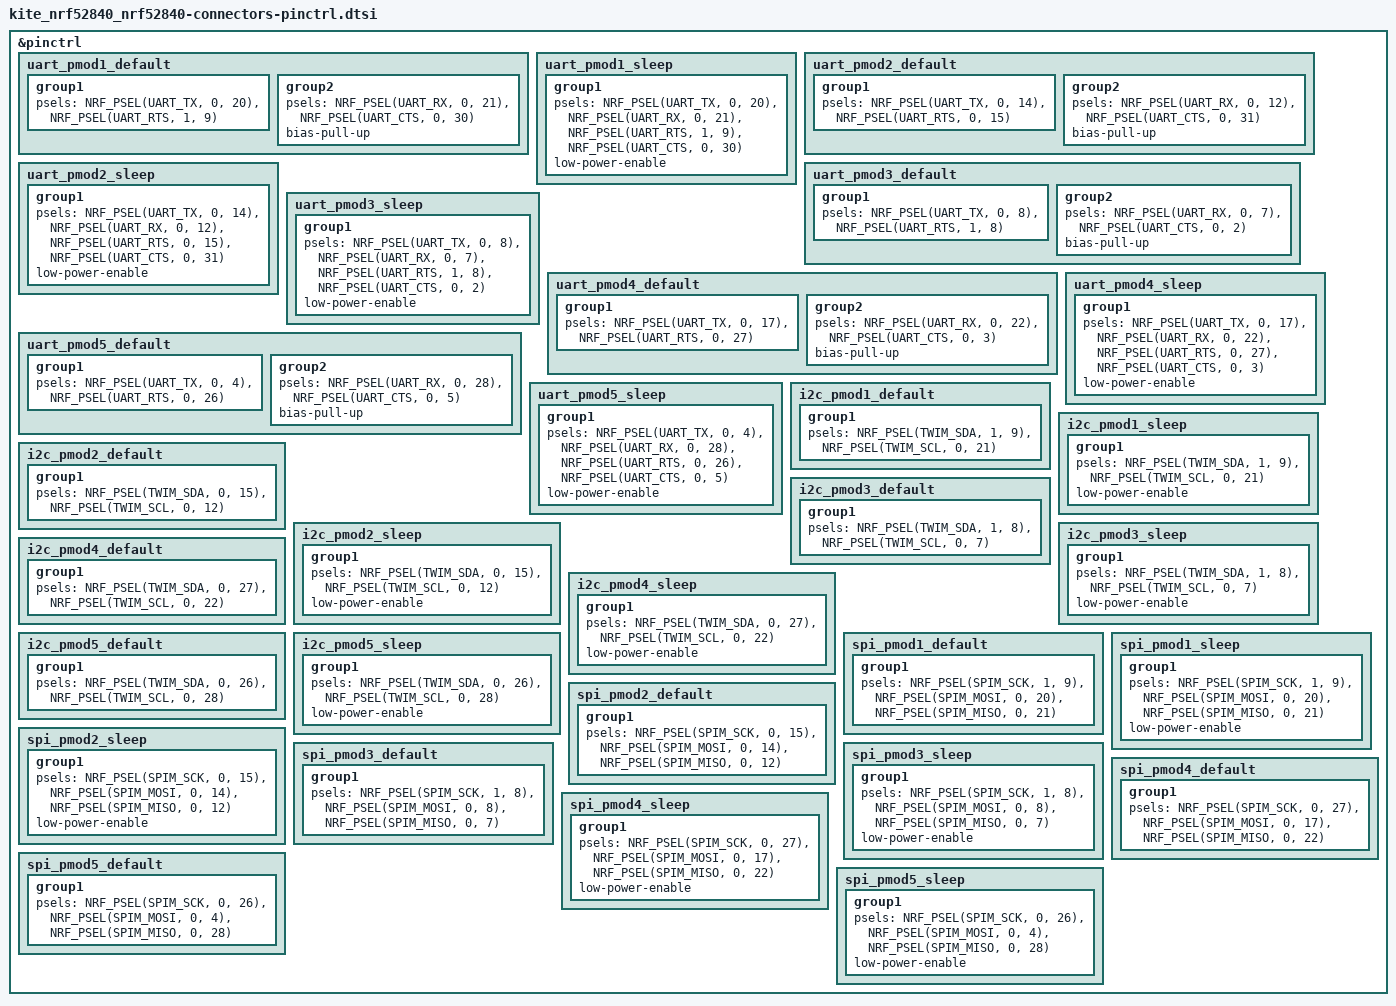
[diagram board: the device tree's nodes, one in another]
/*
 * NOTE: Autogenerated file using gen-connectors-dtsi.py
 *
 * SPDX-License-Identifier: Apache-2.0
 */

&pinctrl {
	/* UART */

	/omit-if-no-ref/ uart_pmod1_default: uart_pmod1_default {
		group1 {
			psels = <NRF_PSEL(UART_TX, 0, 20)>,
				<NRF_PSEL(UART_RTS, 1, 9)>;
		};
		group2 {
			psels = <NRF_PSEL(UART_RX, 0, 21)>,
				<NRF_PSEL(UART_CTS, 0, 30)>;
			bias-pull-up;
		};
	};

	/omit-if-no-ref/ uart_pmod1_sleep: uart_pmod1_sleep {
		group1 {
			psels = <NRF_PSEL(UART_TX, 0, 20)>,
				<NRF_PSEL(UART_RX, 0, 21)>,
				<NRF_PSEL(UART_RTS, 1, 9)>,
				<NRF_PSEL(UART_CTS, 0, 30)>;
			low-power-enable;
		};
	};

	/omit-if-no-ref/ uart_pmod2_default: uart_pmod2_default {
		group1 {
			psels = <NRF_PSEL(UART_TX, 0, 14)>,
				<NRF_PSEL(UART_RTS, 0, 15)>;
		};
		group2 {
			psels = <NRF_PSEL(UART_RX, 0, 12)>,
				<NRF_PSEL(UART_CTS, 0, 31)>;
			bias-pull-up;
		};
	};

	/omit-if-no-ref/ uart_pmod2_sleep: uart_pmod2_sleep {
		group1 {
			psels = <NRF_PSEL(UART_TX, 0, 14)>,
				<NRF_PSEL(UART_RX, 0, 12)>,
				<NRF_PSEL(UART_RTS, 0, 15)>,
				<NRF_PSEL(UART_CTS, 0, 31)>;
			low-power-enable;
		};
	};

	/omit-if-no-ref/ uart_pmod3_default: uart_pmod3_default {
		group1 {
			psels = <NRF_PSEL(UART_TX, 0, 8)>,
				<NRF_PSEL(UART_RTS, 1, 8)>;
		};
		group2 {
			psels = <NRF_PSEL(UART_RX, 0, 7)>,
				<NRF_PSEL(UART_CTS, 0, 2)>;
			bias-pull-up;
		};
	};

	/omit-if-no-ref/ uart_pmod3_sleep: uart_pmod3_sleep {
		group1 {
			psels = <NRF_PSEL(UART_TX, 0, 8)>,
				<NRF_PSEL(UART_RX, 0, 7)>,
				<NRF_PSEL(UART_RTS, 1, 8)>,
				<NRF_PSEL(UART_CTS, 0, 2)>;
			low-power-enable;
		};
	};

	/omit-if-no-ref/ uart_pmod4_default: uart_pmod4_default {
		group1 {
			psels = <NRF_PSEL(UART_TX, 0, 17)>,
				<NRF_PSEL(UART_RTS, 0, 27)>;
		};
		group2 {
			psels = <NRF_PSEL(UART_RX, 0, 22)>,
				<NRF_PSEL(UART_CTS, 0, 3)>;
			bias-pull-up;
		};
	};

	/omit-if-no-ref/ uart_pmod4_sleep: uart_pmod4_sleep {
		group1 {
			psels = <NRF_PSEL(UART_TX, 0, 17)>,
				<NRF_PSEL(UART_RX, 0, 22)>,
				<NRF_PSEL(UART_RTS, 0, 27)>,
				<NRF_PSEL(UART_CTS, 0, 3)>;
			low-power-enable;
		};
	};

	/omit-if-no-ref/ uart_pmod5_default: uart_pmod5_default {
		group1 {
			psels = <NRF_PSEL(UART_TX, 0, 4)>,
				<NRF_PSEL(UART_RTS, 0, 26)>;
		};
		group2 {
			psels = <NRF_PSEL(UART_RX, 0, 28)>,
				<NRF_PSEL(UART_CTS, 0, 5)>;
			bias-pull-up;
		};
	};

	/omit-if-no-ref/ uart_pmod5_sleep: uart_pmod5_sleep {
		group1 {
			psels = <NRF_PSEL(UART_TX, 0, 4)>,
				<NRF_PSEL(UART_RX, 0, 28)>,
				<NRF_PSEL(UART_RTS, 0, 26)>,
				<NRF_PSEL(UART_CTS, 0, 5)>;
			low-power-enable;
		};
	};


	/* I2C */

	/omit-if-no-ref/ i2c_pmod1_default: i2c_pmod1_default {
		group1 {
			psels = <NRF_PSEL(TWIM_SDA, 1, 9)>,
				<NRF_PSEL(TWIM_SCL, 0, 21)>;
		};
	};

	/omit-if-no-ref/ i2c_pmod1_sleep: i2c_pmod1_sleep {
		group1 {
			psels = <NRF_PSEL(TWIM_SDA, 1, 9)>,
				<NRF_PSEL(TWIM_SCL, 0, 21)>;
			low-power-enable;
		};
	};

	/omit-if-no-ref/ i2c_pmod2_default: i2c_pmod2_default {
		group1 {
			psels = <NRF_PSEL(TWIM_SDA, 0, 15)>,
				<NRF_PSEL(TWIM_SCL, 0, 12)>;
		};
	};

	/omit-if-no-ref/ i2c_pmod2_sleep: i2c_pmod2_sleep {
		group1 {
			psels = <NRF_PSEL(TWIM_SDA, 0, 15)>,
				<NRF_PSEL(TWIM_SCL, 0, 12)>;
			low-power-enable;
		};
	};

	/omit-if-no-ref/ i2c_pmod3_default: i2c_pmod3_default {
		group1 {
			psels = <NRF_PSEL(TWIM_SDA, 1, 8)>,
				<NRF_PSEL(TWIM_SCL, 0, 7)>;
		};
	};

	/omit-if-no-ref/ i2c_pmod3_sleep: i2c_pmod3_sleep {
		group1 {
			psels = <NRF_PSEL(TWIM_SDA, 1, 8)>,
				<NRF_PSEL(TWIM_SCL, 0, 7)>;
			low-power-enable;
		};
	};

	/omit-if-no-ref/ i2c_pmod4_default: i2c_pmod4_default {
		group1 {
			psels = <NRF_PSEL(TWIM_SDA, 0, 27)>,
				<NRF_PSEL(TWIM_SCL, 0, 22)>;
		};
	};

	/omit-if-no-ref/ i2c_pmod4_sleep: i2c_pmod4_sleep {
		group1 {
			psels = <NRF_PSEL(TWIM_SDA, 0, 27)>,
				<NRF_PSEL(TWIM_SCL, 0, 22)>;
			low-power-enable;
		};
	};

	/omit-if-no-ref/ i2c_pmod5_default: i2c_pmod5_default {
		group1 {
			psels = <NRF_PSEL(TWIM_SDA, 0, 26)>,
				<NRF_PSEL(TWIM_SCL, 0, 28)>;
		};
	};

	/omit-if-no-ref/ i2c_pmod5_sleep: i2c_pmod5_sleep {
		group1 {
			psels = <NRF_PSEL(TWIM_SDA, 0, 26)>,
				<NRF_PSEL(TWIM_SCL, 0, 28)>;
			low-power-enable;
		};
	};


	/* SPI */

	/omit-if-no-ref/ spi_pmod1_default: spi_pmod1_default {
		group1 {
			psels = <NRF_PSEL(SPIM_SCK, 1, 9)>,
				<NRF_PSEL(SPIM_MOSI, 0, 20)>,
				<NRF_PSEL(SPIM_MISO, 0, 21)>;
		};
	};

	/omit-if-no-ref/ spi_pmod1_sleep: spi_pmod1_sleep {
		group1 {
			psels = <NRF_PSEL(SPIM_SCK, 1, 9)>,
				<NRF_PSEL(SPIM_MOSI, 0, 20)>,
				<NRF_PSEL(SPIM_MISO, 0, 21)>;
			low-power-enable;
		};
	};

	/omit-if-no-ref/ spi_pmod2_default: spi_pmod2_default {
		group1 {
			psels = <NRF_PSEL(SPIM_SCK, 0, 15)>,
				<NRF_PSEL(SPIM_MOSI, 0, 14)>,
				<NRF_PSEL(SPIM_MISO, 0, 12)>;
		};
	};

	/omit-if-no-ref/ spi_pmod2_sleep: spi_pmod2_sleep {
		group1 {
			psels = <NRF_PSEL(SPIM_SCK, 0, 15)>,
				<NRF_PSEL(SPIM_MOSI, 0, 14)>,
				<NRF_PSEL(SPIM_MISO, 0, 12)>;
			low-power-enable;
		};
	};

	/omit-if-no-ref/ spi_pmod3_default: spi_pmod3_default {
		group1 {
			psels = <NRF_PSEL(SPIM_SCK, 1, 8)>,
				<NRF_PSEL(SPIM_MOSI, 0, 8)>,
				<NRF_PSEL(SPIM_MISO, 0, 7)>;
		};
	};

	/omit-if-no-ref/ spi_pmod3_sleep: spi_pmod3_sleep {
		group1 {
			psels = <NRF_PSEL(SPIM_SCK, 1, 8)>,
				<NRF_PSEL(SPIM_MOSI, 0, 8)>,
				<NRF_PSEL(SPIM_MISO, 0, 7)>;
			low-power-enable;
		};
	};

	/omit-if-no-ref/ spi_pmod4_default: spi_pmod4_default {
		group1 {
			psels = <NRF_PSEL(SPIM_SCK, 0, 27)>,
				<NRF_PSEL(SPIM_MOSI, 0, 17)>,
				<NRF_PSEL(SPIM_MISO, 0, 22)>;
		};
	};

	/omit-if-no-ref/ spi_pmod4_sleep: spi_pmod4_sleep {
		group1 {
			psels = <NRF_PSEL(SPIM_SCK, 0, 27)>,
				<NRF_PSEL(SPIM_MOSI, 0, 17)>,
				<NRF_PSEL(SPIM_MISO, 0, 22)>;
			low-power-enable;
		};
	};

	/omit-if-no-ref/ spi_pmod5_default: spi_pmod5_default {
		group1 {
			psels = <NRF_PSEL(SPIM_SCK, 0, 26)>,
				<NRF_PSEL(SPIM_MOSI, 0, 4)>,
				<NRF_PSEL(SPIM_MISO, 0, 28)>;
		};
	};

	/omit-if-no-ref/ spi_pmod5_sleep: spi_pmod5_sleep {
		group1 {
			psels = <NRF_PSEL(SPIM_SCK, 0, 26)>,
				<NRF_PSEL(SPIM_MOSI, 0, 4)>,
				<NRF_PSEL(SPIM_MISO, 0, 28)>;
			low-power-enable;
		};
	};

};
